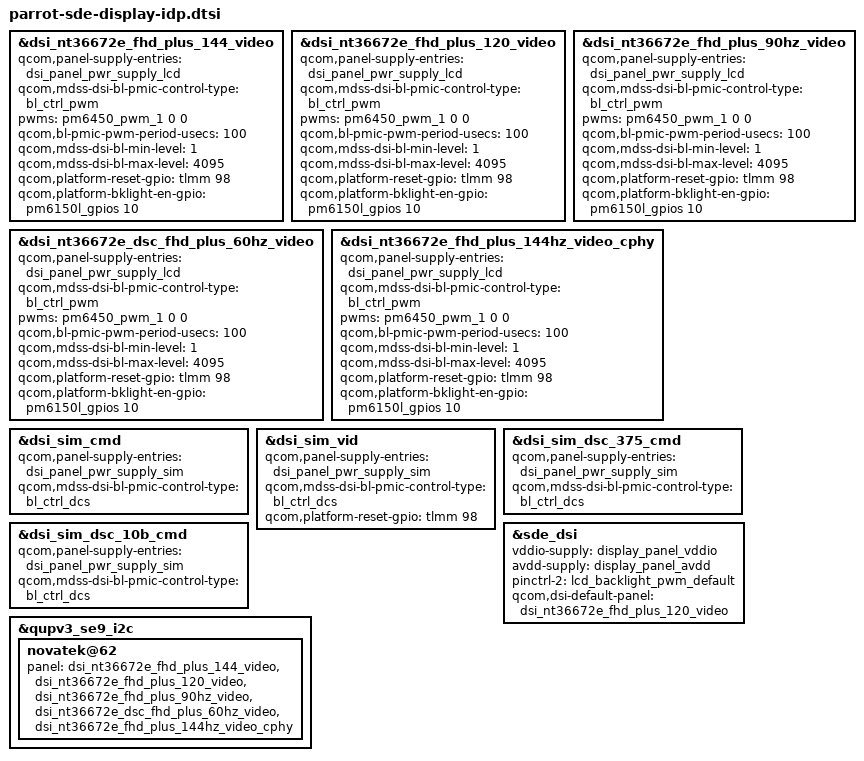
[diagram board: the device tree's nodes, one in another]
#include "parrot-sde-display.dtsi"

&dsi_nt36672e_fhd_plus_144_video {
	qcom,panel-supply-entries = <&dsi_panel_pwr_supply_lcd>;
	qcom,mdss-dsi-bl-pmic-control-type = "bl_ctrl_pwm";
	pwms = <&pm6450_pwm_1 0 0>;
	qcom,bl-pmic-pwm-period-usecs = <100>;
	qcom,mdss-dsi-bl-min-level = <1>;
	qcom,mdss-dsi-bl-max-level = <4095>;
	qcom,platform-reset-gpio = <&tlmm 98 0>;
	qcom,platform-bklight-en-gpio = <&pm6150l_gpios 10 0>;
};

&dsi_nt36672e_fhd_plus_120_video {
	qcom,panel-supply-entries = <&dsi_panel_pwr_supply_lcd>;
	qcom,mdss-dsi-bl-pmic-control-type = "bl_ctrl_pwm";
	pwms = <&pm6450_pwm_1 0 0>;
	qcom,bl-pmic-pwm-period-usecs = <100>;
	qcom,mdss-dsi-bl-min-level = <1>;
	qcom,mdss-dsi-bl-max-level = <4095>;
	qcom,platform-reset-gpio = <&tlmm 98 0>;
	qcom,platform-bklight-en-gpio = <&pm6150l_gpios 10 0>;
};

&dsi_nt36672e_fhd_plus_90hz_video {
	qcom,panel-supply-entries = <&dsi_panel_pwr_supply_lcd>;
	qcom,mdss-dsi-bl-pmic-control-type = "bl_ctrl_pwm";
	pwms = <&pm6450_pwm_1 0 0>;
	qcom,bl-pmic-pwm-period-usecs = <100>;
	qcom,mdss-dsi-bl-min-level = <1>;
	qcom,mdss-dsi-bl-max-level = <4095>;
	qcom,platform-reset-gpio = <&tlmm 98 0>;
	qcom,platform-bklight-en-gpio = <&pm6150l_gpios 10 0>;
};

&dsi_nt36672e_dsc_fhd_plus_60hz_video {
	qcom,panel-supply-entries = <&dsi_panel_pwr_supply_lcd>;
	qcom,mdss-dsi-bl-pmic-control-type = "bl_ctrl_pwm";
	pwms = <&pm6450_pwm_1 0 0>;
	qcom,bl-pmic-pwm-period-usecs = <100>;
	qcom,mdss-dsi-bl-min-level = <1>;
	qcom,mdss-dsi-bl-max-level = <4095>;
	qcom,platform-reset-gpio = <&tlmm 98 0>;
	qcom,platform-bklight-en-gpio = <&pm6150l_gpios 10 0>;
};

&dsi_nt36672e_fhd_plus_144hz_video_cphy {
	qcom,panel-supply-entries = <&dsi_panel_pwr_supply_lcd>;
	qcom,mdss-dsi-bl-pmic-control-type = "bl_ctrl_pwm";
	pwms = <&pm6450_pwm_1 0 0>;
	qcom,bl-pmic-pwm-period-usecs = <100>;
	qcom,mdss-dsi-bl-min-level = <1>;
	qcom,mdss-dsi-bl-max-level = <4095>;
	qcom,platform-reset-gpio = <&tlmm 98 0>;
	qcom,platform-bklight-en-gpio = <&pm6150l_gpios 10 0>;
};

&dsi_sim_cmd {
	qcom,panel-supply-entries = <&dsi_panel_pwr_supply_sim>;
	qcom,mdss-dsi-bl-pmic-control-type = "bl_ctrl_dcs";
};

&dsi_sim_vid {
	qcom,panel-supply-entries = <&dsi_panel_pwr_supply_sim>;
	qcom,mdss-dsi-bl-pmic-control-type = "bl_ctrl_dcs";
	qcom,platform-reset-gpio = <&tlmm 98 0>;
};

&dsi_sim_dsc_375_cmd {
	qcom,panel-supply-entries = <&dsi_panel_pwr_supply_sim>;
	qcom,mdss-dsi-bl-pmic-control-type = "bl_ctrl_dcs";
};

&dsi_sim_dsc_10b_cmd {
	qcom,panel-supply-entries = <&dsi_panel_pwr_supply_sim>;
	qcom,mdss-dsi-bl-pmic-control-type = "bl_ctrl_dcs";
};

&sde_dsi {
	vddio-supply = <&display_panel_vddio>;
	avdd-supply = <&display_panel_avdd>;

	pinctrl-names = "panel_active", "panel_suspend", "pwm_pin";
	pinctrl-2 = <&lcd_backlight_pwm_default>;

	qcom,dsi-default-panel = <&dsi_nt36672e_fhd_plus_120_video>;
};

&qupv3_se9_i2c {
	novatek@62 {
		panel = <&dsi_nt36672e_fhd_plus_144_video
			&dsi_nt36672e_fhd_plus_120_video
			&dsi_nt36672e_fhd_plus_90hz_video
			&dsi_nt36672e_dsc_fhd_plus_60hz_video
			&dsi_nt36672e_fhd_plus_144hz_video_cphy>;
	};
};
